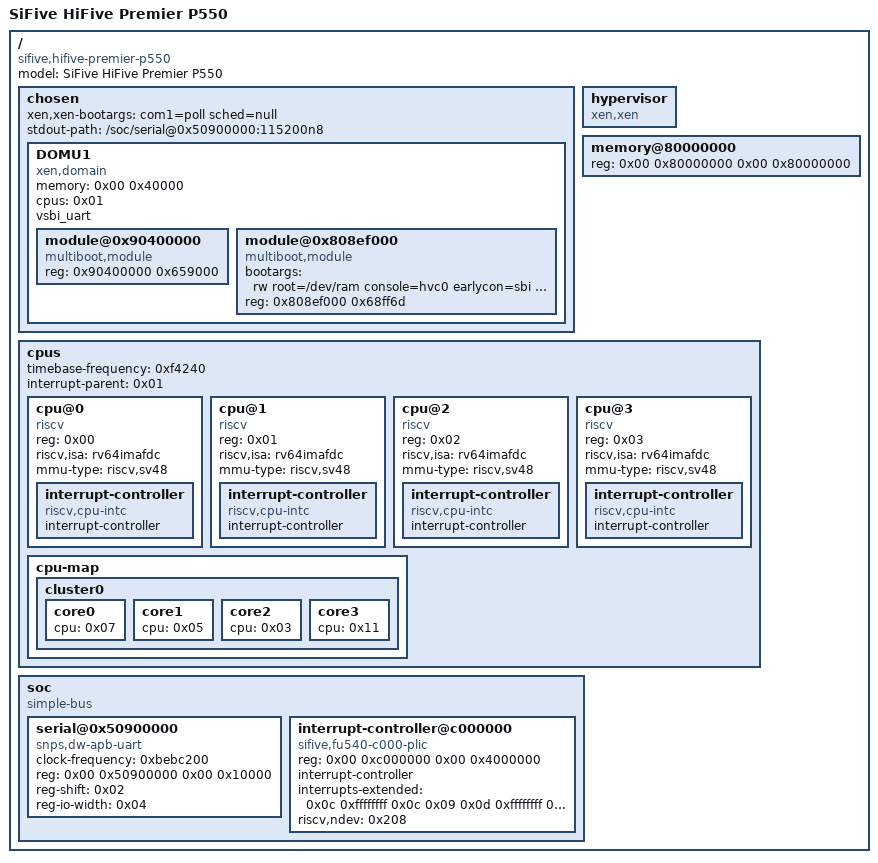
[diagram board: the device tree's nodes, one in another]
/dts-v1/;

/ {
	#address-cells = <0x02>;
	#size-cells = <0x02>;
	compatible = "sifive,hifive-premier-p550", "eswin,eic7700";
	model = "SiFive HiFive Premier P550";

	chosen {
		xen,xen-bootargs = "com1=poll sched=null";
		stdout-path = "/soc/serial@0x50900000:115200n8";

		DOMU1 {
			#address-cells = <0x01>;
			#size-cells = <0x01>;
			compatible = "xen,domain";
			memory = <0x00 0x40000>;
			cpus = <0x01>;
			vsbi_uart;

			module@0x90400000 {
				compatible = "multiboot,module", "multiboot,ramdisk";
				reg = <0x90400000 0x659000>;
			};

			module@0x808ef000 {
				bootargs = "rw root=/dev/ram console=hvc0 earlycon=sbi earlyprintk keep_bootcon bootmem_debug debug";
				compatible = "multiboot,module", "multiboot,kernel";
				reg = <0x808ef000 0x68ff6d>;
			};
		};
	};

	hypervisor {
		compatible = "xen,xen";
		#address-cells = <0x02>;
		#size-cells = <0x02>;
	};

	memory@80000000 {
		device_type = "memory";
		reg = <0x00 0x80000000 0x00 0x80000000>;
	};

	cpus {
		#address-cells = <0x01>;
		#size-cells = <0x00>;
		timebase-frequency = <0xf4240>;
		interrupt-parent = <0x01>;

		cpu@0 {
			phandle = <0x07>;
			device_type = "cpu";
			compatible = "riscv";
			reg = <0x00>;
			riscv,isa = "rv64imafdc";
			mmu-type = "riscv,sv48";
			status = "okay";

			interrupt-controller {
				#interrupt-cells = <0x01>;
				compatible = "riscv,cpu-intc";
				interrupt-controller;
				phandle = <0x0f>;
			};
		};

		cpu@1 {
			phandle = <0x05>;
			device_type = "cpu";
			compatible = "riscv";
			reg = <0x01>;
			riscv,isa = "rv64imafdc";
			mmu-type = "riscv,sv48";
			status = "okay";

			interrupt-controller {
				#interrupt-cells = <0x01>;
				interrupt-controller;
				compatible = "riscv,cpu-intc";
			};
		};

		cpu@2 {
			phandle = <0x03>;
			device_type = "cpu";
			compatible = "riscv";
			reg = <0x02>;
			riscv,isa = "rv64imafdc";
			mmu-type = "riscv,sv48";
			status = "okay";

			interrupt-controller {
				#interrupt-cells = <0x01>;
				interrupt-controller;
				compatible = "riscv,cpu-intc";
			};
		};

		cpu@3 {
			phandle = <0x11>;
			device_type = "cpu";
			compatible = "riscv";
			reg = <0x03>;
			riscv,isa = "rv64imafdc";
			mmu-type = "riscv,sv48";
			status = "okay";

			interrupt-controller {
				#interrupt-cells = <0x01>;
				interrupt-controller;
				compatible = "riscv,cpu-intc";
			};
		};

		cpu-map {

			cluster0 {

				core0 {
					cpu = <0x07>;
				};

				core1 {
					cpu = <0x05>;
				};

				core2 {
					cpu = <0x03>;
				};

				core3 {
					cpu = <0x11>;
				};
			};
		};
	};

	soc {
		#address-cells = <0x02>;
		#size-cells = <0x02>;
		compatible = "simple-bus";
		ranges;

		serial@0x50900000 {
			compatible = "snps,dw-apb-uart";
			clock-frequency = <0xbebc200>;
			reg = <0x00 0x50900000 0x00 0x10000>;
			reg-shift = <0x02>;
			reg-io-width = <0x04>;
			status = "okay";
		};

		interrupt-controller@c000000 {
			compatible = "sifive,fu540-c000-plic", "sifive,plic-1.0.0";
			reg = <0x00 0xc000000 0x00 0x4000000>;
			#address-cells = <0x00>;
			#interrupt-cells = <0x01>;
			interrupt-controller;
			interrupts-extended = <0x0c 0xffffffff 0x0c 0x09 0x0d 0xffffffff 0x0d 0x09 0x0e 0xffffffff 0x0e 0x09 0x0f 0xffffffff 0x0f 0x09>;
			riscv,ndev = <0x208>;
			phandle = <0x01>;
		};
	};
};
